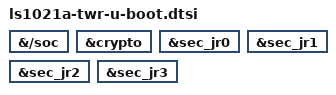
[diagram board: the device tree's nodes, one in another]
// SPDX-License-Identifier: GPL-2.0-or-later
/*
 * Copyright 2022 NXP
 */

&{/soc} {
	bootph-pre-ram;
	bootph-all;
};

&crypto {
	bootph-pre-ram;
};

&sec_jr0 {
	bootph-pre-ram;
};

&sec_jr1 {
	bootph-pre-ram;
};

&sec_jr2 {
	bootph-pre-ram;
};

&sec_jr3 {
	bootph-pre-ram;
};
